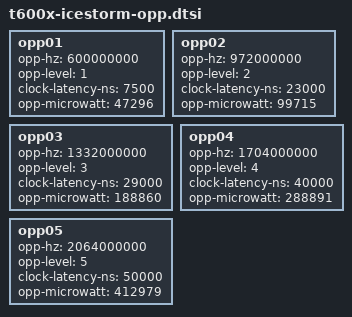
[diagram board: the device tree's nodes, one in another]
// SPDX-License-Identifier: GPL-2.0+ OR MIT
/*
 * Operating points for Apple T600x Icestorm (E-cluster) cores.
 *
 * Copyright The Asahi Linux Contributors
 */

		opp01 {
			opp-hz = /bits/ 64 <600000000>;
			opp-level = <1>;
			clock-latency-ns = <7500>;
			opp-microwatt = <47296>;
		};
		opp02 {
			opp-hz = /bits/ 64 <972000000>;
			opp-level = <2>;
			clock-latency-ns = <23000>;
			opp-microwatt = <99715>;
		};
		opp03 {
			opp-hz = /bits/ 64 <1332000000>;
			opp-level = <3>;
			clock-latency-ns = <29000>;
			opp-microwatt = <188860>;
		};
		opp04 {
			opp-hz = /bits/ 64 <1704000000>;
			opp-level = <4>;
			clock-latency-ns = <40000>;
			opp-microwatt = <288891>;
		};
		opp05 {
			opp-hz = /bits/ 64 <2064000000>;
			opp-level = <5>;
			clock-latency-ns = <50000>;
			opp-microwatt = <412979>;
		};
